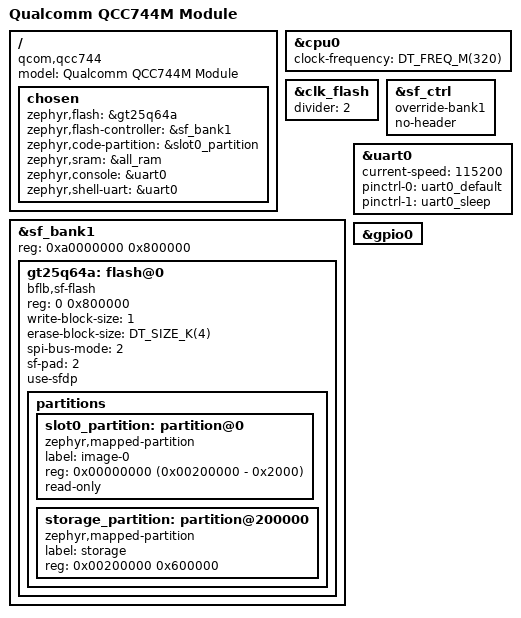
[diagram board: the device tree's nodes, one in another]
/*
 * Copyright (c) 2025-2026 MASSDRIVER EI (massdriver.space)
 *
 * SPDX-License-Identifier: Apache-2.0
 */

#include <bflb/bl618.dtsi>
#include "qcc744m-pinctrl.dtsi"

/ {
	model = "Qualcomm QCC744M Module";
	compatible = "qcom,qcc744";

	chosen {
		zephyr,flash = &gt25q64a;
		zephyr,flash-controller = &sf_bank1;
		zephyr,code-partition = &slot0_partition;
		zephyr,sram = &all_ram;
		zephyr,console = &uart0;
		zephyr,shell-uart = &uart0;
	};
};

&cpu0 {
	clock-frequency = <DT_FREQ_M(320)>;
};

&clk_flash {
	divider = <2>;
};

&sf_ctrl {
	override-bank1;
	no-header;
};

&sf_bank1 {
	reg = <0xa0000000 0x800000>;
	ranges = <0x0 0xa0000000 0x800000>;

	gt25q64a: flash@0 {
		compatible = "bflb,sf-flash", "soc-nv-flash";
		reg = <0 0x800000>;
		write-block-size = <1>;
		erase-block-size = <DT_SIZE_K(4)>;

		spi-bus-mode = <2>;
		sf-pad = <2>;
		use-sfdp;

		partitions {
			#address-cells = <1>;
			#size-cells = <1>;

			slot0_partition: partition@0 {
				compatible = "zephyr,mapped-partition";
				label = "image-0";
				reg = <0x00000000 (0x00200000 - 0x2000)>;
				read-only;
			};

			storage_partition: partition@200000 {
				compatible = "zephyr,mapped-partition";
				label = "storage";
				reg = <0x00200000 0x600000>;
			};
		};
	};
};

&uart0 {
	status = "okay";
	current-speed = <115200>;

	pinctrl-0 = <&uart0_default>;
	pinctrl-1 = <&uart0_sleep>;
	pinctrl-names = "default", "sleep";
};

&gpio0 {
	status = "okay";
};
